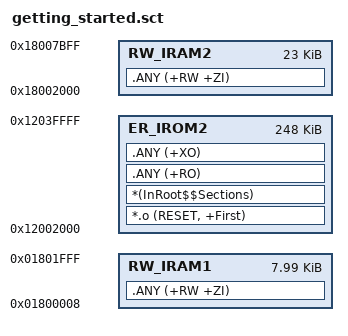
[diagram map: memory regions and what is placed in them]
; *************************************************************
; *** Scatter-Loading Description File generated by uVision ***
; *************************************************************

LR_IROM2 0x12002000 0x0003E000  {
  ER_IROM2 0x12002000 0x0003E000  {  ; load address = execution address
   *.o (RESET, +First)
   *(InRoot$$Sections)
   .ANY (+RO)
   .ANY (+XO)
  }
  RW_IRAM1 0x01800008 0x00001FF8  {  ; RW data
   .ANY (+RW +ZI)
  }
  RW_IRAM2 0x18002000 0x00005C00  {
   .ANY (+RW +ZI)
  }
}


